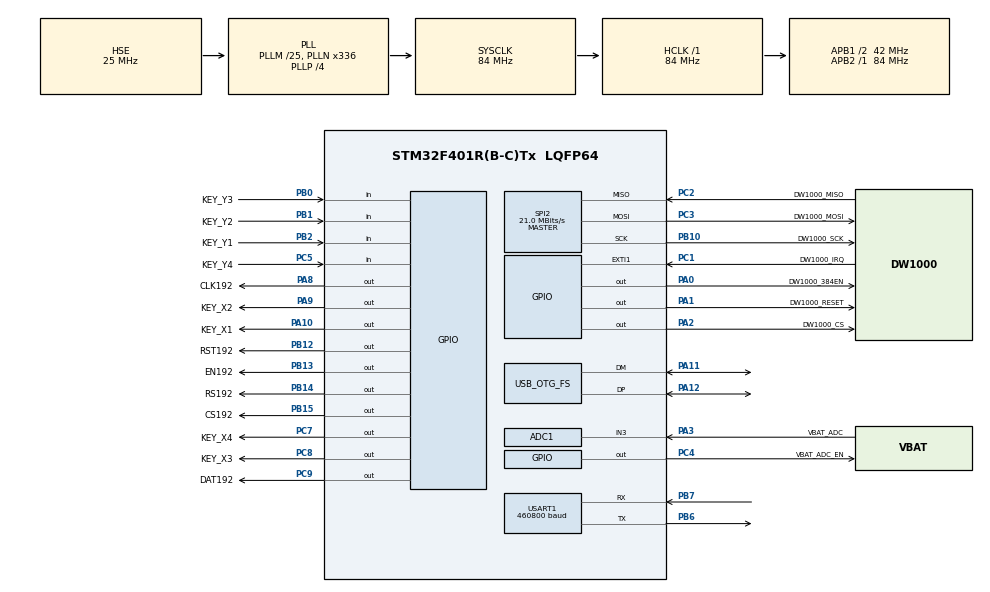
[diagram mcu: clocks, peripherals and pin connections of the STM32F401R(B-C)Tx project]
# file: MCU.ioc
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ADC1.Channel-0\#ChannelRegularConversion=ADC_CHANNEL_3
ADC1.Channel-1\#ChannelRegularConversion=ADC_CHANNEL_VREFINT
ADC1.NbrOfConversion=2
ADC1.NbrOfConversionFlag=1
ADC1.Rank-0\#ChannelRegularConversion=1
ADC1.Rank-1\#ChannelRegularConversion=2
ADC1.SamplingTime-0\#ChannelRegularConversion=ADC_SAMPLETIME_112CYCLES
ADC1.SamplingTime-1\#ChannelRegularConversion=ADC_SAMPLETIME_112CYCLES
ADC1.master=1
Dma.ADC1.0.Direction=DMA_PERIPH_TO_MEMORY
Dma.ADC1.0.FIFOMode=DMA_FIFOMODE_DISABLE
Dma.ADC1.0.Instance=DMA2_Stream0
Dma.ADC1.0.MemDataAlignment=DMA_MDATAALIGN_HALFWORD
Dma.ADC1.0.MemInc=DMA_MINC_ENABLE
Dma.ADC1.0.Mode=DMA_NORMAL
Dma.ADC1.0.PeriphDataAlignment=DMA_PDATAALIGN_HALFWORD
Dma.ADC1.0.PeriphInc=DMA_PINC_DISABLE
Dma.ADC1.0.Priority=DMA_PRIORITY_LOW
Dma.Request0=ADC1
Mcu.Family=STM32F4
Mcu.Name=STM32F401R(B-C)Tx
Mcu.Package=LQFP64
NVIC.DMA2_Stream0_IRQn=true\:0\:0\:false\:false\:true\:false\:true
NVIC.EXTI1_IRQn=true\:0\:0\:false\:false\:true\:true\:true
NVIC.OTG_FS_IRQn=true\:0\:0\:false\:false\:true\:false\:true
NVIC.PriorityGroup=NVIC_PRIORITYGROUP_4
PA0-WKUP.GPIO_Label=DW1000_384EN
PA0-WKUP.Signal=GPIO_Output
PA1.GPIO_Label=DW1000_RESET
PA1.GPIO_ModeDefaultOutputPP=GPIO_MODE_OUTPUT_OD
PA1.Signal=GPIO_Output
PA10.GPIO_Label=KEY_X1
PA10.GPIO_ModeDefaultOutputPP=GPIO_MODE_OUTPUT_PP
PA10.GPIO_PuPd=GPIO_NOPULL
PA10.GPIO_Speed=GPIO_SPEED_FREQ_LOW
PA10.PinState=GPIO_PIN_RESET
PA10.Signal=GPIO_Output
PA11.Mode=Device_Only
PA11.Signal=USB_OTG_FS_DM
PA12.Mode=Device_Only
PA12.Signal=USB_OTG_FS_DP
PA13.Mode=Serial_Wire
PA13.Signal=SYS_JTMS-SWDIO
PA14.Mode=Serial_Wire
PA14.Signal=SYS_JTCK-SWCLK
PA2.GPIO_Label=DW1000_CS
PA2.Signal=GPIO_Output
PA3.GPIO_Label=VBAT_ADC
PA3.Signal=ADCx_IN3
PA8.GPIO_Label=CLK192
PA8.Signal=GPIO_Output
PA9.GPIO_Label=KEY_X2
PA9.GPIO_ModeDefaultOutputPP=GPIO_MODE_OUTPUT_PP
PA9.GPIO_PuPd=GPIO_NOPULL
PA9.GPIO_Speed=GPIO_SPEED_FREQ_LOW
PA9.PinState=GPIO_PIN_RESET
PA9.Signal=GPIO_Output
PB0.GPIO_Label=KEY_Y3
PB0.GPIO_PuPd=GPIO_PULLDOWN
PB0.Signal=GPIO_Input
PB1.GPIO_Label=KEY_Y2
PB1.GPIO_PuPd=GPIO_PULLDOWN
PB1.Signal=GPIO_Input
PB10.GPIO_Label=DW1000_SCK
PB10.Mode=Full_Duplex_Master
PB10.Signal=SPI2_SCK
PB12.GPIO_Label=RST192
PB12.Signal=GPIO_Output
PB13.GPIO_Label=EN192
PB13.PinState=GPIO_PIN_SET
PB13.Signal=GPIO_Output
PB14.GPIO_Label=RS192
PB14.Signal=GPIO_Output
PB15.GPIO_Label=CS192
PB15.Signal=GPIO_Output
PB2.GPIO_Label=KEY_Y1
PB2.GPIO_PuPd=GPIO_PULLDOWN
PB2.Signal=GPIO_Input
PB6.Mode=Asynchronous
PB6.Signal=USART1_TX
PB7.Mode=Asynchronous
PB7.Signal=USART1_RX
PC1.GPIO_Label=DW1000_IRQ
PC1.GPIO_PuPd=GPIO_PULLDOWN
PC1.Signal=GPXTI1
PC2.GPIO_Label=DW1000_MISO
PC2.Mode=Full_Duplex_Master
PC2.Signal=SPI2_MISO
PC3.GPIO_Label=DW1000_MOSI
PC3.Mode=Full_Duplex_Master
PC3.Signal=SPI2_MOSI
PC4.GPIO_Label=VBAT_ADC_EN
PC4.GPIO_ModeDefaultOutputPP=GPIO_MODE_OUTPUT_OD
PC4.Signal=GPIO_Output
PC5.GPIO_Label=KEY_Y4
PC5.GPIO_PuPd=GPIO_PULLDOWN
PC5.Signal=GPIO_Input
PC7.GPIO_Label=KEY_X4
PC7.GPIO_ModeDefaultOutputPP=GPIO_MODE_OUTPUT_PP
PC7.GPIO_PuPd=GPIO_NOPULL
PC7.GPIO_Speed=GPIO_SPEED_FREQ_LOW
PC7.PinState=GPIO_PIN_RESET
PC7.Signal=GPIO_Output
PC8.GPIO_Label=KEY_X3
PC8.GPIO_ModeDefaultOutputPP=GPIO_MODE_OUTPUT_PP
PC8.GPIO_PuPd=GPIO_NOPULL
PC8.GPIO_Speed=GPIO_SPEED_FREQ_LOW
PC8.PinState=GPIO_PIN_RESET
PC8.Signal=GPIO_Output
PC9.GPIO_Label=DAT192
PC9.GPIO_ModeDefaultOutputPP=GPIO_MODE_OUTPUT_PP
PC9.GPIO_PuPd=GPIO_PULLUP
PC9.GPIO_Speed=GPIO_SPEED_FREQ_HIGH
PC9.PinState=GPIO_PIN_SET
PC9.Signal=GPIO_Output
PH0\ -\ OSC_IN.Mode=HSE-External-Oscillator
PH0\ -\ OSC_IN.Signal=RCC_OSC_IN
PH1\ -\ OSC_OUT.Mode=HSE-External-Oscillator
PH1\ -\ OSC_OUT.Signal=RCC_OSC_OUT
ProjectManager.HeapSize=0x200
ProjectManager.StackSize=0x400
ProjectManager.TargetToolchain=MDK-ARM V5.27
RCC.48MHZClocksFreq_Value=48000000
RCC.AHBFreq_Value=84000000
RCC.APB1CLKDivider=RCC_HCLK_DIV2
RCC.APB1Freq_Value=42000000
RCC.APB1TimFreq_Value=84000000
RCC.APB2Freq_Value=84000000
RCC.APB2TimFreq_Value=84000000
RCC.CortexFreq_Value=84000000
RCC.HCLKFreq_Value=84000000
RCC.HSE_VALUE=25000000
RCC.HSI_VALUE=16000000
RCC.LSE_VALUE=32768
RCC.PLLM=25
RCC.PLLN=336
RCC.PLLP=RCC_PLLP_DIV4
RCC.PLLQ=7
RCC.SYSCLKFreq_VALUE=84000000
RCC.SYSCLKSource=RCC_SYSCLKSOURCE_PLLCLK
RCC.VCOOutputFreq_Value=336000000
SH.ADCx_IN3.0=ADC1_IN3,IN3
SPI2.BaudRatePrescaler=SPI_BAUDRATEPRESCALER_2
SPI2.CalculateBaudRate=21.0 MBits/s
SPI2.Direction=SPI_DIRECTION_2LINES
SPI2.Mode=SPI_MODE_MASTER
SPI2.VirtualType=VM_MASTER
USART1.BaudRate=460800
USART1.VirtualMode=VM_ASYNC
USB_DEVICE.CLASS_NAME_FS=CDC
USB_DEVICE.VirtualMode=Cdc
USB_DEVICE.VirtualModeFS=Cdc_FS
USB_OTG_FS.VirtualMode=Device_Only
VP_ADC1_Vref_Input.Mode=IN-Vrefint
VP_TIM1_VS_ClockSourceINT.Mode=Internal
VP_USB_DEVICE_VS_USB_DEVICE_CDC_FS.Mode=CDC_FS
board=custom

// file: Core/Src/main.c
/* USER CODE BEGIN Header */
/**
  ******************************************************************************
  * @file           : main.c
  * @brief          : Main program body
  ******************************************************************************
  * @attention
  *
  * <h2><center>&copy; Copyright (c) 2021 STMicroelectronics.
  * All rights reserved.</center></h2>
  *
  * This software component is licensed by ST under BSD 3-Clause license,
  * the "License"; You may not use this file except in compliance with the
  * License. You may obtain a copy of the License at:
  *                        opensource.org/licenses/BSD-3-Clause
  *
  ******************************************************************************
  */
/* USER CODE END Header */
#include "main.h"
#include "adc.h"
#include "dma.h"
#include "spi.h"
#include "tim.h"
#include "usart.h"
#include "usb_device.h"
#include "gpio.h"

/* USER CODE BEGIN Includes */
#include "usbd_rndis_core.h"
extern rndis_rxproc_t rndis_rxproc;
/* USER CODE END Includes */

void SystemClock_Config(void);

/* USER CODE BEGIN 0 */
void rxproc(const char *data, int size){
	HAL_UART_Transmit(&huart1,(uint8_t*)data,size,1000);
}
/* USER CODE END 0 */

int main(void)
{

  /* MCU Configuration--------------------------------------------------------*/

  /* Reset of all peripherals, Initializes the Flash interface and the Systick. */
  HAL_Init();

  /* Configure the system clock */
  SystemClock_Config();

  /* Initialize all configured peripherals */
  MX_GPIO_Init();
  MX_DMA_Init();
  MX_SPI2_Init();
  MX_TIM1_Init();
  MX_USART1_UART_Init();
  MX_ADC1_Init();
  MX_USB_DEVICE_Init();
  /* USER CODE BEGIN 2 */

//HAL_Delay(10000);
		HAL_Delay(1000);
rndis_rxproc=rxproc;
  /* USER CODE END 2 */

  /* Infinite loop */
  while (1)
  {

    /* USER CODE BEGIN 3 */
		static char data[1024]="eset of all peripherals, Initializes the Flash interface and the Systick"
			"eset of all peripherals, Initializes the Flash interface and the Systick"
			"	eset of all peripherals, Initializes the Flash interface and the Systick"
			"		eset of all peripherals, Initializes the Flash interface and the Systick"
			"			eset of all peripherals, Initializes the Flash interface and the Systick";
		rndis_send(data, 50);
		HAL_Delay(1000);
  }
  /* USER CODE END 3 */
}

void SystemClock_Config(void)
{
  RCC_OscInitTypeDef RCC_OscInitStruct = {0};
  RCC_ClkInitTypeDef RCC_ClkInitStruct = {0};

  /** Configure the main internal regulator output voltage
  */
  __HAL_RCC_PWR_CLK_ENABLE();
  __HAL_PWR_VOLTAGESCALING_CONFIG(PWR_REGULATOR_VOLTAGE_SCALE2);
  /** Initializes the RCC Oscillators according to the specified parameters
  * in the RCC_OscInitTypeDef structure.
  */
  RCC_OscInitStruct.OscillatorType = RCC_OSCILLATORTYPE_HSE;
  RCC_OscInitStruct.HSEState = RCC_HSE_ON;
  RCC_OscInitStruct.PLL.PLLState = RCC_PLL_ON;
  RCC_OscInitStruct.PLL.PLLSource = RCC_PLLSOURCE_HSE;
  RCC_OscInitStruct.PLL.PLLM = 25;
  RCC_OscInitStruct.PLL.PLLN = 336;
  RCC_OscInitStruct.PLL.PLLP = RCC_PLLP_DIV4;
  RCC_OscInitStruct.PLL.PLLQ = 7;
  if (HAL_RCC_OscConfig(&RCC_OscInitStruct) != HAL_OK)
  {
    Error_Handler();
  }
  /** Initializes the CPU, AHB and APB buses clocks
  */
  RCC_ClkInitStruct.ClockType = RCC_CLOCKTYPE_HCLK|RCC_CLOCKTYPE_SYSCLK
                              |RCC_CLOCKTYPE_PCLK1|RCC_CLOCKTYPE_PCLK2;
  RCC_ClkInitStruct.SYSCLKSource = RCC_SYSCLKSOURCE_PLLCLK;
  RCC_ClkInitStruct.AHBCLKDivider = RCC_SYSCLK_DIV1;
  RCC_ClkInitStruct.APB1CLKDivider = RCC_HCLK_DIV2;
  RCC_ClkInitStruct.APB2CLKDivider = RCC_HCLK_DIV1;

  if (HAL_RCC_ClockConfig(&RCC_ClkInitStruct, FLASH_LATENCY_2) != HAL_OK)
  {
    Error_Handler();
  }
}

void Error_Handler(void)
{
  __disable_irq();
  while (1)
  {
  }
}

/************************ (C) COPYRIGHT STMicroelectronics *****END OF FILE****/
